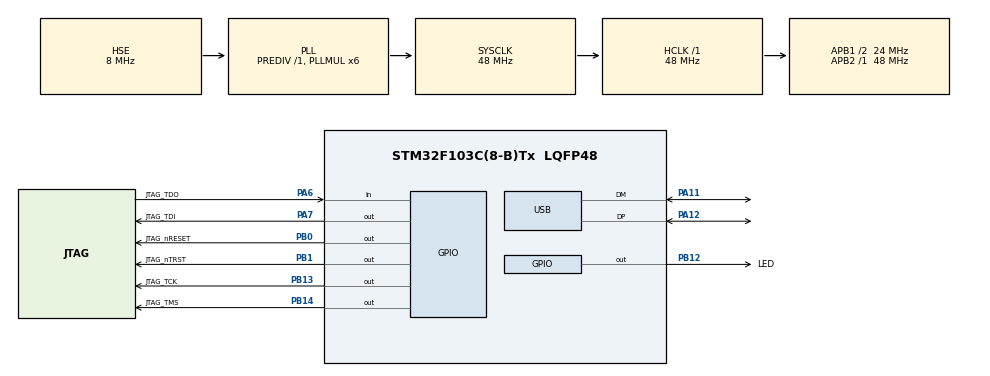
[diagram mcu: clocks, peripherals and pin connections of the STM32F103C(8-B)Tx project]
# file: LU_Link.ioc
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Mcu.Family=STM32F1
Mcu.Name=STM32F103C(8-B)Tx
Mcu.Package=LQFP48
NVIC.PriorityGroup=NVIC_PRIORITYGROUP_4
NVIC.USB_LP_CAN1_RX0_IRQn=true\:0\:0\:false\:false\:true\:false\:true\:true
PA11.Mode=Device
PA11.Signal=USB_DM
PA12.Mode=Device
PA12.Signal=USB_DP
PA13.Mode=Serial_Wire
PA13.Signal=SYS_JTMS-SWDIO
PA14.Mode=Serial_Wire
PA14.Signal=SYS_JTCK-SWCLK
PA6.GPIO_Label=JTAG_TDO
PA6.Signal=GPIO_Input
PA7.GPIO_Label=JTAG_TDI
PA7.GPIO_Speed=GPIO_SPEED_FREQ_HIGH
PA7.Signal=GPIO_Output
PB0.GPIO_Label=JTAG_nRESET
PB0.GPIO_Speed=GPIO_SPEED_FREQ_HIGH
PB0.PinState=GPIO_PIN_SET
PB0.Signal=GPIO_Output
PB1.GPIO_Label=JTAG_nTRST
PB1.GPIO_PuPd=GPIO_PULLUP
PB1.GPIO_Speed=GPIO_SPEED_FREQ_HIGH
PB1.PinState=GPIO_PIN_SET
PB1.Signal=GPIO_Output
PB12.GPIO_Label=LED
PB12.GPIO_Speed=GPIO_SPEED_FREQ_HIGH
PB12.PinState=GPIO_PIN_SET
PB12.Signal=GPIO_Output
PB13.GPIO_Label=JTAG_TCK
PB13.GPIO_PuPd=GPIO_PULLUP
PB13.GPIO_Speed=GPIO_SPEED_FREQ_HIGH
PB13.PinState=GPIO_PIN_SET
PB13.Signal=GPIO_Output
PB14.GPIO_Label=JTAG_TMS
PB14.GPIO_Speed=GPIO_SPEED_FREQ_HIGH
PB14.PinState=GPIO_PIN_SET
PB14.Signal=GPIO_Output
PD0-OSC_IN.Mode=HSE-External-Oscillator
PD0-OSC_IN.Signal=RCC_OSC_IN
PD1-OSC_OUT.Mode=HSE-External-Oscillator
PD1-OSC_OUT.Signal=RCC_OSC_OUT
ProjectManager.HeapSize=0x2000
ProjectManager.StackSize=0x2000
ProjectManager.TargetToolchain=MDK-ARM V5.32
RCC.AHBFreq_Value=48000000
RCC.APB1CLKDivider=RCC_HCLK_DIV2
RCC.APB1Freq_Value=24000000
RCC.APB1TimFreq_Value=48000000
RCC.APB2Freq_Value=48000000
RCC.APB2TimFreq_Value=48000000
RCC.HCLKFreq_Value=48000000
RCC.PLLMUL=RCC_PLL_MUL6
RCC.PLLSourceVirtual=RCC_PLLSOURCE_HSE
RCC.SYSCLKFreq_VALUE=48000000
RCC.SYSCLKSource=RCC_SYSCLKSOURCE_PLLCLK
RCC.USBFreq_Value=48000000
USB_DEVICE.CLASS_NAME_FS=CUSTOM_HID
USB_DEVICE.CONFIGURATION_STRING_CUSTOMHID_FS=DAP HID Config
USB_DEVICE.CUSTOM_HID_FS_BINTERVAL=0x1
USB_DEVICE.INTERFACE_STRING_CUSTOMHID_FS=DAP HID Interface
USB_DEVICE.PRODUCT_STRING_CUSTOMHID_FS=CMSIS-DAP
USB_DEVICE.USBD_CUSTOMHID_OUTREPORT_BUF_SIZE=64
USB_DEVICE.USBD_CUSTOM_HID_REPORT_DESC_SIZE=32
USB_DEVICE.USBD_MAX_STR_DESC_SIZ=24
USB_DEVICE.VirtualMode=CustomHid
USB_DEVICE.VirtualModeFS=Custom_Hid_FS
VP_USB_DEVICE_VS_USB_DEVICE_CUSTOM_HID_FS.Mode=CUSTOM_HID_FS
board=custom

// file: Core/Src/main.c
/* USER CODE BEGIN Header */
/**
  ******************************************************************************
  * @file           : main.c
  * @brief          : Main program body
  ******************************************************************************
  * @attention
  *
  * Copyright (c) 2023 STMicroelectronics.
  * All rights reserved.
  *
  * This software is licensed under terms that can be found in the LICENSE file
  * in the root directory of this software component.
  * If no LICENSE file comes with this software, it is provided AS-IS.
  *
  ******************************************************************************
  */
/* USER CODE END Header */
#include "main.h"
#include "usb_device.h"
#include "gpio.h"

/* USER CODE BEGIN Includes */
#include "DAP_config.h"
#include "DAP.h"
/* USER CODE END Includes */

void SystemClock_Config(void);

/* USER CODE BEGIN 0 */
extern __NO_RETURN void DAP_Thread(void *argument);
/* USER CODE END 0 */

int main(void)
{

  /* MCU Configuration--------------------------------------------------------*/

  /* Reset of all peripherals, Initializes the Flash interface and the Systick. */
  HAL_Init();

  /* Configure the system clock */
  SystemClock_Config();

  /* USER CODE BEGIN SysInit */
	MX_GPIO_Init();
	CoreDebug->DEMCR |= CoreDebug_DEMCR_TRCENA_Msk;

	DWT->CYCCNT = 0;
	DWT->CTRL |= DWT_CTRL_CYCCNTENA_Msk;

	DAP_Setup();
	MX_USB_DEVICE_Init();
	DAP_Thread(NULL);
  /* USER CODE END SysInit */

  /* Initialize all configured peripherals */

  /* Infinite loop */
  while (1)
  {

  }
}

void SystemClock_Config(void)
{
  RCC_OscInitTypeDef RCC_OscInitStruct = {0};
  RCC_ClkInitTypeDef RCC_ClkInitStruct = {0};
  RCC_PeriphCLKInitTypeDef PeriphClkInit = {0};

  /** Initializes the RCC Oscillators according to the specified parameters
  * in the RCC_OscInitTypeDef structure.
  */
  RCC_OscInitStruct.OscillatorType = RCC_OSCILLATORTYPE_HSE;
  RCC_OscInitStruct.HSEState = RCC_HSE_ON;
  RCC_OscInitStruct.HSEPredivValue = RCC_HSE_PREDIV_DIV1;
  RCC_OscInitStruct.HSIState = RCC_HSI_ON;
  RCC_OscInitStruct.PLL.PLLState = RCC_PLL_ON;
  RCC_OscInitStruct.PLL.PLLSource = RCC_PLLSOURCE_HSE;
  RCC_OscInitStruct.PLL.PLLMUL = RCC_PLL_MUL6;
  if (HAL_RCC_OscConfig(&RCC_OscInitStruct) != HAL_OK)
  {
    Error_Handler();
  }

  /** Initializes the CPU, AHB and APB buses clocks
  */
  RCC_ClkInitStruct.ClockType = RCC_CLOCKTYPE_HCLK|RCC_CLOCKTYPE_SYSCLK
                              |RCC_CLOCKTYPE_PCLK1|RCC_CLOCKTYPE_PCLK2;
  RCC_ClkInitStruct.SYSCLKSource = RCC_SYSCLKSOURCE_PLLCLK;
  RCC_ClkInitStruct.AHBCLKDivider = RCC_SYSCLK_DIV1;
  RCC_ClkInitStruct.APB1CLKDivider = RCC_HCLK_DIV2;
  RCC_ClkInitStruct.APB2CLKDivider = RCC_HCLK_DIV1;

  if (HAL_RCC_ClockConfig(&RCC_ClkInitStruct, FLASH_LATENCY_1) != HAL_OK)
  {
    Error_Handler();
  }
  PeriphClkInit.PeriphClockSelection = RCC_PERIPHCLK_USB;
  PeriphClkInit.UsbClockSelection = RCC_USBCLKSOURCE_PLL;
  if (HAL_RCCEx_PeriphCLKConfig(&PeriphClkInit) != HAL_OK)
  {
    Error_Handler();
  }
}

void Error_Handler(void)
{
  __disable_irq();
  while (1)
  {
  }
}
